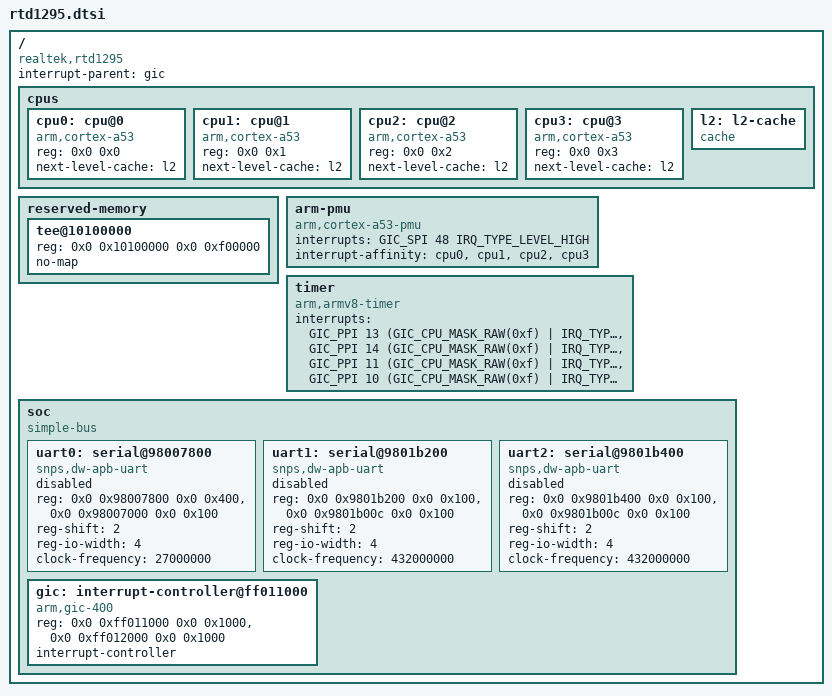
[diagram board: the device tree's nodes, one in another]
/*
 * Copyright (c) 2016-2017 Andreas Färber
 *
 * This file is dual-licensed: you can use it either under the terms
 * of the GPL or the X11 license, at your option. Note that this dual
 * licensing only applies to this file, and not this project as a
 * whole.
 *
 *  a) This library is free software; you can redistribute it and/or
 *     modify it under the terms of the GNU General Public License as
 *     published by the Free Software Foundation; either version 2 of the
 *     License, or (at your option) any later version.
 *
 *     This library is distributed in the hope that it will be useful,
 *     but WITHOUT ANY WARRANTY; without even the implied warranty of
 *     MERCHANTABILITY or FITNESS FOR A PARTICULAR PURPOSE.  See the
 *     GNU General Public License for more details.
 *
 * Or, alternatively,
 *
 *  b) Permission is hereby granted, free of charge, to any person
 *     obtaining a copy of this software and associated documentation
 *     files (the "Software"), to deal in the Software without
 *     restriction, including without limitation the rights to use,
 *     copy, modify, merge, publish, distribute, sublicense, and/or
 *     sell copies of the Software, and to permit persons to whom the
 *     Software is furnished to do so, subject to the following
 *     conditions:
 *
 *     The above copyright notice and this permission notice shall be
 *     included in all copies or substantial portions of the Software.
 *
 *     THE SOFTWARE IS PROVIDED "AS IS", WITHOUT WARRANTY OF ANY KIND,
 *     EXPRESS OR IMPLIED, INCLUDING BUT NOT LIMITED TO THE WARRANTIES
 *     OF MERCHANTABILITY, FITNESS FOR A PARTICULAR PURPOSE AND
 *     NONINFRINGEMENT. IN NO EVENT SHALL THE AUTHORS OR COPYRIGHT
 *     HOLDERS BE LIABLE FOR ANY CLAIM, DAMAGES OR OTHER LIABILITY,
 *     WHETHER IN AN ACTION OF CONTRACT, TORT OR OTHERWISE, ARISING
 *     FROM, OUT OF OR IN CONNECTION WITH THE SOFTWARE OR THE USE OR
 *     OTHER DEALINGS IN THE SOFTWARE.
 */

#include <dt-bindings/interrupt-controller/irq.h>
#include <dt-bindings/interrupt-controller/arm-gic.h>

/ {
	compatible = "realtek,rtd1295";
	interrupt-parent = <&gic>;
	#address-cells = <2>;
	#size-cells = <2>;

	cpus {
		#address-cells = <2>;
		#size-cells = <0>;

		cpu0: cpu@0 {
			device_type = "cpu";
			compatible = "arm,cortex-a53", "arm,armv8";
			reg = <0x0 0x0>;
			next-level-cache = <&l2>;
		};

		cpu1: cpu@1 {
			device_type = "cpu";
			compatible = "arm,cortex-a53", "arm,armv8";
			reg = <0x0 0x1>;
			next-level-cache = <&l2>;
		};

		cpu2: cpu@2 {
			device_type = "cpu";
			compatible = "arm,cortex-a53", "arm,armv8";
			reg = <0x0 0x2>;
			next-level-cache = <&l2>;
		};

		cpu3: cpu@3 {
			device_type = "cpu";
			compatible = "arm,cortex-a53", "arm,armv8";
			reg = <0x0 0x3>;
			next-level-cache = <&l2>;
		};

		l2: l2-cache {
			compatible = "cache";
		};
	};

	reserved-memory {
		#address-cells = <2>;
		#size-cells = <2>;
		ranges;

		tee@10100000 {
			reg = <0x0 0x10100000 0x0 0xf00000>;
			no-map;
		};
	};

	arm-pmu {
		compatible = "arm,cortex-a53-pmu";
		interrupts = <GIC_SPI 48 IRQ_TYPE_LEVEL_HIGH>;
		interrupt-affinity = <&cpu0>, <&cpu1>, <&cpu2>, <&cpu3>;
	};

	timer {
		compatible = "arm,armv8-timer";
		interrupts = <GIC_PPI 13
			(GIC_CPU_MASK_RAW(0xf) | IRQ_TYPE_LEVEL_LOW)>,
			     <GIC_PPI 14
			(GIC_CPU_MASK_RAW(0xf) | IRQ_TYPE_LEVEL_LOW)>,
			     <GIC_PPI 11
			(GIC_CPU_MASK_RAW(0xf) | IRQ_TYPE_LEVEL_LOW)>,
			     <GIC_PPI 10
			(GIC_CPU_MASK_RAW(0xf) | IRQ_TYPE_LEVEL_LOW)>;
	};

	soc {
		compatible = "simple-bus";
		#address-cells = <2>;
		#size-cells = <2>;
		ranges;

		uart0: serial@98007800 {
			compatible = "snps,dw-apb-uart";
			reg = <0x0 0x98007800 0x0 0x400>,
			      <0x0 0x98007000 0x0 0x100>;
			reg-shift = <2>;
			reg-io-width = <4>;
			clock-frequency = <27000000>;
			status = "disabled";
		};

		uart1: serial@9801b200 {
			compatible = "snps,dw-apb-uart";
			reg = <0x0 0x9801b200 0x0 0x100>,
			      <0x0 0x9801b00c 0x0 0x100>;
			reg-shift = <2>;
			reg-io-width = <4>;
			clock-frequency = <432000000>;
			status = "disabled";
		};

		uart2: serial@9801b400 {
			compatible = "snps,dw-apb-uart";
			reg = <0x0 0x9801b400 0x0 0x100>,
			      <0x0 0x9801b00c 0x0 0x100>;
			reg-shift = <2>;
			reg-io-width = <4>;
			clock-frequency = <432000000>;
			status = "disabled";
		};

		gic: interrupt-controller@ff011000 {
			compatible = "arm,gic-400";
			reg = <0x0 0xff011000 0x0 0x1000>,
			      <0x0 0xff012000 0x0 0x1000>;
			interrupt-controller;
			#interrupt-cells = <3>;
		};
	};
};
